# EPWM_EPWM_50020000h register map
Vendor: Texas Instruments
Registers are 16-bit, read-write, reset 0x0 unless marked. A register's access mark holds for its fields unless they carry their own. Offsets are as the file gives them; [hi:lo] are bit positions; {n}, {i} and the like mark numbered series; 'fields as' and 'values as' point back to an identical list; <NAME> marks a mode.

## EPWM (part 4 of 4)
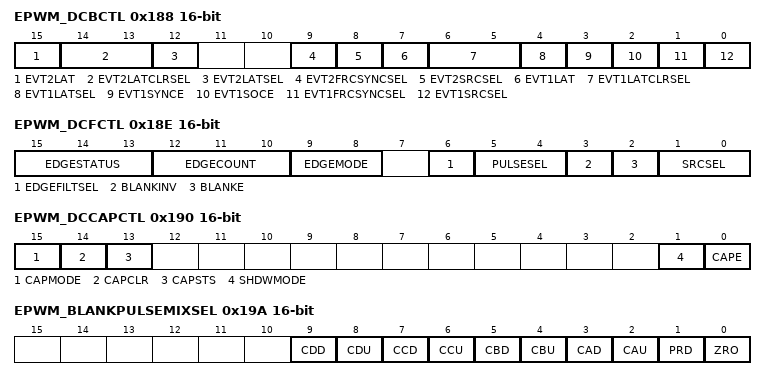
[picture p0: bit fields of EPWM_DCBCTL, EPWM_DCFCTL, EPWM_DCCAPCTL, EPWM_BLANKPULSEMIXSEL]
0x188 EPWM_DCBCTL access per field — Digital Compare B Control Register.
  [15] EVT2LAT ro — Indicates the status of DCBEVT2LAT signal. 0 The DCBEVT2LAT latch is cleared. 1 The DCBEVT2LAT latch is set.
  [14:13] EVT2LATCLRSEL rw — DCBEVT2 Latched clear source select: 00 CNT_ZERO event clears DCBEVT2 latch. 01 PRD_EQ event clears DCBEVT2 latch. 10 CNT_ZERO event or PRD_EQ event clears DCBEVT2 latch. 11 Reserved.
  [12] EVT2LATSEL rw — DCBEVT2 Latched signal select: 0 Does not select the DCBEVT2 latched signal as source of DCBEVT2.force. 1 Selects the DCBEVT2 latched signal as source of DCBEVT2.force.
  [9] EVT2FRCSYNCSEL rw — DCBEVT2 Force Synchronization Signal Select 0:Source is synchronized with EPWMCLK 1:Source is passed through asynchronously
  [8] EVT2SRCSEL rw — DCBEVT2 Source Signal Select 0:Source Is DCBEVT2 Signal 1:Source Is DCEVTFILT Signal
  [7] EVT1LAT ro — Indicates the status of DCBEVT1LAT signal. 0 The DCBEVT1LAT latch is cleared. 1 The DCBEVT1LAT latch is set.
  [6:5] EVT1LATCLRSEL rw — DCBEVT1 Latched clear source select: 00 CNT_ZERO event clears DCBEVT1 latch. 01 PRD_EQ event clears DCBEVT1 latch. 10 CNT_ZERO event or PRD_EQ event clears DCBEVT1 latch. 11 Reserved.
  [4] EVT1LATSEL rw — DCBEVT1 Latched signal select: 0 Does not select the DCBEVT1 latched signal as source of DCBEVT1.force. 1 Selects the DCBEVT1 latched signal as source of DCBEVT1.force.
  [3] EVT1SYNCE rw — DCBEVT1 SYNC, Enable/Disable 0:SYNC Generation Disabled 1:SYNC Generation Enabled
  [2] EVT1SOCE rw — DCBEVT1 SOC, Enable/Disable 0:SOC Generation Disabled 1:SOC Generation Enabled
  [1] EVT1FRCSYNCSEL rw — DCBEVT1 Force Synchronization Signal Select 0:Source is synchronized with EPWMCLK 1:Source is passed through asynchronously
  [0] EVT1SRCSEL rw — DCBEVT1 Source Signal Select 0:Source Is DCBEVT1 Signal 1:Source Is DCEVTFILT Signal
0x18E EPWM_DCFCTL access per field — Digital Compare Filter Control Register.
  [15:13] EDGESTATUS ro — Edge Status: These bits reflect the total number of edges currently captured. When the value matches the EDGECOUNT, the status bits are set to zero. and a TBCLK wide pulse is generated which can then be output on the DCEVTFILT signal. The edge counter can be reset by Writing 000 to the EDGECOUNT value:
  [12:10] EDGECOUNT rw — Edge Count: These bits select how many edges to count before generating a TBCLK wide pulse on the DCEVTFILT signal: 000:no edges, reset current EDGESTATUS bits to 3'b000 001:1 edge 010:2 edges 011:3 edges 100:4 edges 101:5 edges 110:6 edges 111:7 edges
  [9:8] EDGEMODE rw — Edge Mode Select: 00:Low To High Edge 01:High To Low Edge 10:Both Edges 11:Reserved
  [6] EDGEFILTSEL rw — Edge Filter Select: 0:Edge Filter Not Selected 1:Edge Filter Selected
  [5:4] PULSESEL rw — Pulse Select For Blanking & Capture Alignment 00:Time-base counter equal to period [TBCTR = TBPRD] 01:Time-base counter equal to zero [TBCTR = 0x00] 10:Time-base counter equal to zero [TBCTR = 0x00] or period [TBCTR = TBPRD] 11:Blank Pulse Mix
  [3] BLANKINV rw — Blanking Window Inversion 0:Blanking window not inverted 1:Blanking window inverted
  [2] BLANKE rw — Blanking Window Enable/Disable 0:Blanking window is disabled 1:Blanking window is enabled
  [1:0] SRCSEL rw — Filter Block Signal Source Select 00:Source Is DCAEVT1 Signal 01:Source Is DCAEVT2 Signal 10:Source Is DCBEVT1 Signal 11:Source Is DCBEVT2 Signal
0x190 EPWM_DCCAPCTL access not given — Digital Compare Capture Control Register.
  [15] CAPMODE rw — Counter Capture Mode 0:When a DCEVTFILT occurs and the counter capture is enabled, then the current TBCNT value is captured in the active register. When the respective trip event occurs, further trip [capture] events are ignored until the next PRD_eq or CNT_zero event [as selected by the PULSESEL bit in the DCFCTL register] re-triggers the capture mechanism. If active mode is enabled, via SHDWMODE bit in DCC0PCTL register, CPU reads of this register will return the active register value. If shadow mode is enabled, via SHDWMODE bit in DCC0PCTL register, the active register is copied to the shadow register on the PRD_eq or CNT_zero event [whichever is selected by PULSESEL bit in DCFCTL register]. CPU reads of this register will return the shadow register value. 1:When a DCEVTFILT occurs and the counter capture is enabled, then the current TBCNT value is captured in the active register. When the respective trip event occurs - it will set the CAPSTS flag and further trip [capture] events are ignored until this bit is cleared. CAPSTS can be cleared by writing to CAPCLR bit in DCC0PCTL register and it re-triggers the capture mechanism. If active mode is enabled, via SHDWMODE bit in DCC0PCTL register, CPU reads of this register will return the active register value. If shadow mode is enabled, via SHDWMODE bit in DCC0PCTL register, the active register is copied to the shadow register on the PRD_eq or CNT_zero event [whichever is selected by PULSESEL bit in DCFCTL register]. CPU reads of this register will return the shadow register value.
  [14] CAPCLR — DC Capture Latched Status Clear Flag 0:Writing a 0 has no effect. 1:Writing a 1 will clear this CAPSTS [set] condition. (access R/W1TS)
  [13] CAPSTS ro — Latched Status Flag for Capture Event 0:No DC capture event occurred. 1:A DC capture event has occurred.
  [1] SHDWMODE rw — TBCTR Counter Capture Shadow Select Mode 0:Enable shadow mode. The DCC0P active register is copied to shadow register on a TBCTR = TBPRD or TBCTR = zero event as defined by the DCFCTL[PULSESEL] bit. CPU reads of the DCC0P register will return the shadow register contents. 1:Active Mode. In this mode the shadow register is disabled. CPU reads from the DCC0P register will always return the active register contents.
  [0] CAPE rw — TBCTR Counter Capture Enable/Disable 0:Disable the time-base counter capture. 1:Enable the time-base counter capture.
0x192 EPWM_DCFOFFSET — Digital Compare Filter Offset Register .
  [15:0] DCFOFFSET — Blanking Window Offset These 16-bits specify the number of TBCLK cycles from the blanking window reference to the point when the blanking window is applied. The blanking window reference is either period or zero as defined by the DCFCTL[PULSESEL] bit. This offset register is shadowed and the active register is loaded at the reference point defined by DCFCTL[PULSESEL]. The offset counter is also initialized and begins to count down when the active register is loaded. When the counter expires, the blanking window is applied. If the blanking window is currently active, then the blanking window counter is restarted.
0x194 EPWM_DCFOFFSETCNT ro — Digital Compare Filter Offset Counter Register.
  [15:0] DCFOFFSETCNT — Blanking Offset Counter These 16-bits are read only and indicate the current value of the offset counter. The counter counts down to zero and then stops until it is re-loaded on the next period or zero event as defined by the DCFCTL[PULSESEL] bit. The offset counter is not affected by the free/soft emulation bits. That is, it will always continue to count down if the device is halted by a emulation stop.
0x196 EPWM_DCFWINDOW — Digital Compare Filter Window Register.
  [15:0] DCFWINDOW — Blanking Window Width 00h No blanking window is generated. 01-FFFFh: Specifies the width of the blanking window in TBCLK cycles. The blanking window begins when the offset counter expires. When this occurs, the window counter is loaded and begins to count down. If the blanking window is currently active and the offset counter expires, the blanking window counter is not restarted and the blanking window is cut short prematurely. Care should be taken to avoid this situation. The blanking window can cross a PWM period boundary.
0x198 EPWM_DCFWINDOWCNT ro — Digital Compare Filter Window Counter Register.
  [15:0] DCFWINDOWCNT — Blanking Window Counter These 16 bits are read only and indicate the current value of the window counter. The counter counts down to zero and then stops until it is re-loaded when the offset counter reaches zero again.
0x19A EPWM_BLANKPULSEMIXSEL — Blanking window trigger pulse select register.
  [9] CDD — Enable event time-base counter equal to CMPD when the timer is decrementing to the blanking window trigger [BLANKPULSEMIX]. 0:CMPD down-count match enable event is not enabled 1:Enable CMPD down-count match enable event
  [8] CDU — Enable event time-base counter equal to CMPD when the timer is incrementing to the blanking window trigger [BLANKPULSEMIX]. 0:CMPD up-count match enable event is not enabled 1:Enable CMPD up-count match enable event
  [7] CCD — Enable event time-base counter equal to CMPC when the timer is decrementing to the blanking window trigger [BLANKPULSEMIX]. 0:CMPC down-count match enable event is not enabled 1:Enable CMPC down-count match enable event
  [6] CCU — Enable event time-base counter equal to CMPC when the timer is incrementing to the blanking window trigger [BLANKPULSEMIX]. 0:CMPC up-count match enable event is not enabled 1:Enable CMPC up-count match enable event
  [5] CBD — Enable event time-base counter equal to CMPB when the timer is decrementing to the blanking window trigger [BLANKPULSEMIX]. 0:CMPB down-count match enable event is not enabled 1:Enable CMPB down-count match enable event
  [4] CBU — Enable event time-base counter equal to CMPB when the timer is incrementing to the mixed ET interrupt trigger signal [BLANKPULSEMIX]. 0:CMPB up-count match enable event is not enabled 1:Enable CMPB up-count match enable event
  [3] CAD — Enable event time-base counter equal to CMPA when the timer is decrementing to the blanking window trigger [BLANKPULSEMIX]. 0:CMPA down-count match enable event is not enabled 1:Enable CMPA down-count match enable event
  [2] CAU — Enable event time-base counter equal to CMPA when the timer is incrementing to the blanking window trigger [BLANKPULSEMIX]. 0:CMPA up-count match enable event is not enabled 1:Enable CMPA up-count match enable event
  [1] PRD — Enable event time-base counter equal to period [TBCTR = TBPRD] to the blanking window trigger [BLANKPULSEMIX]. 0:Period match event is not enabled 1:Enable period match event
  [0] ZRO — Enable event time-base counter equal to zero [TBCTR = 0x00] to the blanking window trigger [BLANKPULSEMIX]. 0:Zero match event is not enabled 1:Enable zero match event
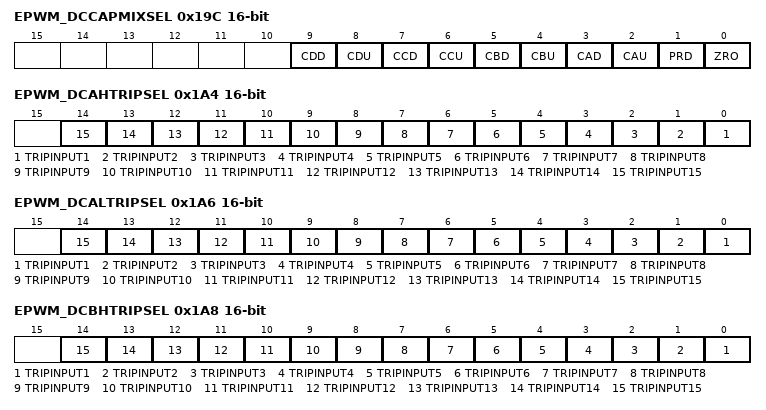
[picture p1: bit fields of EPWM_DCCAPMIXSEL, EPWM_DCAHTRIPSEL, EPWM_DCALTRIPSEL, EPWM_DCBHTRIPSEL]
0x19C EPWM_DCCAPMIXSEL — Capture Event pulse select register.
  [9] CDD — Enable event time-base counter equal to CMPD when the timer is decrementing to the blanking window trigger [DCC0PMIX]. 0:CMPD down-count match enable event is not enabled 1:Enable CMPD down-count match enable event
  [8] CDU — Enable event time-base counter equal to CMPD when the timer is incrementing to the blanking window trigger [DCC0PMIX]. 0:CMPD up-count match enable event is not enabled 1:Enable CMPD up-count match enable event
  [7] CCD — Enable event time-base counter equal to CMPC when the timer is decrementing to the blanking window trigger [DCC0PMIX]. 0:CMPC down-count match enable event is not enabled 1:Enable CMPC down-count match enable event
  [6] CCU — Enable event time-base counter equal to CMPC when the timer is incrementing to the blanking window trigger [DCC0PMIX]. 0:CMPC up-count match enable event is not enabled 1:Enable CMPC up-count match enable event
  [5] CBD — Enable event time-base counter equal to CMPB when the timer is decrementing to the blanking window trigger [DCC0PMIX]. 0:CMPB down-count match enable event is not enabled 1:Enable CMPB down-count match enable event
  [4] CBU — Enable event time-base counter equal to CMPB when the timer is incrementing to the mixed ET interrupt trigger signal [DCC0PMIX]. 0:CMPB up-count match enable event is not enabled 1:Enable CMPB up-count match enable event
  [3] CAD — Enable event time-base counter equal to CMPA when the timer is decrementing to the blanking window trigger [DCC0PMIX]. 0:CMPA down-count match enable event is not enabled 1:Enable CMPA down-count match enable event
  [2] CAU — Enable event time-base counter equal to CMPA when the timer is incrementing to the blanking window trigger [DCC0PMIX]. 0:CMPA up-count match enable event is not enabled 1:Enable CMPA up-count match enable event
  [1] PRD — Enable event time-base counter equal to period [TBCTR = TBPRD] to the blanking window trigger [DCC0PMIX]. 0:Period match event is not enabled 1:Enable period match event
  [0] ZRO — Enable event time-base counter equal to zero [TBCTR = 0x00] to the blanking window trigger [DCC0PMIX]. 0:Zero match event is not enabled 1:Enable zero match event
0x19E EPWM_DCCAP ro — Digital Compare Counter Capture Register .
  [15:0] DCCAP — Digital Compare Time-Base Counter Capture To enable time-base counter capture, set the DCC0PCLT[CAPE] bit to 1. If enabled, reflects the value of the time-base counter [TBCTR] on the low to high edge transition of a filtered [DCEVTFLT] event. Further capture events are ignored until the next period or zero as selected by the DCFCTL[PULSESEL] bit. Shadowing of DCC0P is enabled and disabled by the DCC0PCTL[SHDWMODE] bit. By default this register is shadowed. - If DCC0PCTL[SHDWMODE] = 0, then the shadow is enabled. In this mode, the active register is copied to the shadow register on the TBCTR = TBPRD or TBCTR = zero as defined by the DCFCTL[PULSESEL] bit. CPU reads of this register will return the shadow register value. - If DCC0PCTL[SHDWMODE] = 1, then the shadow register is disabled. In this mode, CPU reads will return the active register value. The active and shadow registers share the same memory map address.
0x1A4 EPWM_DCAHTRIPSEL — Digital Compare AH Trip Select .
  [n-1] TRIPINPUT{n} (n=1..15) — TRIP Input {n} 0:Trip Input {n} not selected as combinational ORed input 1:Trip Input {n} selected as combinational ORed input to DCAH mux
0x1A6 EPWM_DCALTRIPSEL — Digital Compare AL Trip Select .
  [n-1] TRIPINPUT{n} (n=1..15) — TRIP Input {n} 0:Trip Input {n} not selected as combinational ORed input 1:Trip Input {n} selected as combinational ORed input to DCAL mux
0x1A8 EPWM_DCBHTRIPSEL — Digital Compare BH Trip Select .
  [n-1] TRIPINPUT{n} (n=1..15) — TRIP Input {n} 0:Trip Input {n} not selected as combinational ORed input 1:Trip Input {n} selected as combinational ORed input to DCBH mux
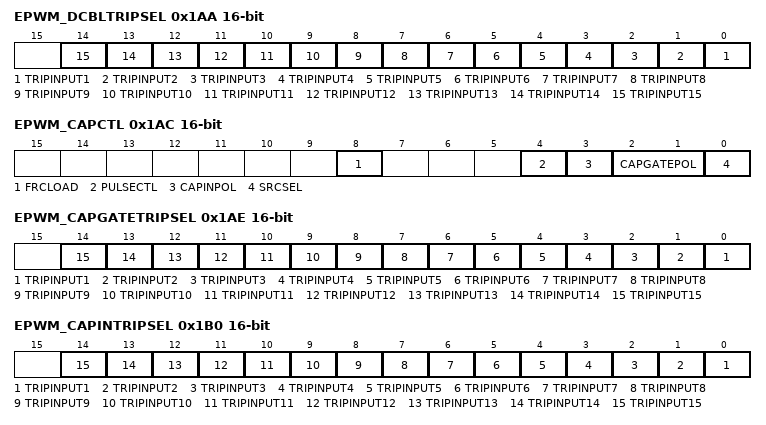
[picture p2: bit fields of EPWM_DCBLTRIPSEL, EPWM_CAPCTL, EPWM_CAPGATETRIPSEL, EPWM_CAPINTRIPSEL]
0x1AA EPWM_DCBLTRIPSEL — Digital Compare BL Trip Select .
  fields as EPWM_DCALTRIPSEL
0x1AC EPWM_CAPCTL access not given — Event Capture Control Register.
  [8] FRCLOAD — 0:Writing of 0 is ignored. Always reads back a 0. 1:Forces a LOAD to occur on the DCC0P - an equivalent LOAD.active pulse (access R/W1TS)
  [4] PULSECTL rw — Capture Input Polarity Select Mux: 0:Pulse selection determined by PULSESEL bits [common pulse selection for Blanking and Capture logic] 1:Pulse selection determined by CAPMIXSEL register [independent pulse selection for Blaning and Capture logic]
  [3] CAPINPOL rw — Capture Input Polarity Select Mux: 0:CAPIN.sync not inverted 1:CAPIN.sync Inverted Default state assumption for these inputs can be active high. If the user is providing active low signal then invert option can be configured
  [2:1] CAPGATEPOL rw — Capture Gate Input Polarity Select Mux: 00:Set to 1 - Gate is always ON 01:Set to 0 - Gate is always OFF 10:CAPGATE.sync 11:CAPGATE.sync Inverted Default state assumption for these inputs can be active high. If the user is providing active low signal then invert option can be configured
  [0] SRCSEL rw — Capture Logic Input Select Mux: 0:DCEVTFILT [Sync] - same as Type-4 1:CAPIN.sync
0x1AE EPWM_CAPGATETRIPSEL — Event Capture Gate Trip input select.
  [n-1] TRIPINPUT{n} (n=1..15) — TRIP Input {n} 0:Trip Input {n} not selected as combinational ORed input 1:Trip Input {n} selected as combinational ORed input to CAPGATE mux
0x1B0 EPWM_CAPINTRIPSEL — Event Capture Trip input select.
  [n-1] TRIPINPUT{n} (n=1..15) — TRIP Input {n} 0:Trip Input {n} not selected as combinational ORed input 1:Trip Input {n} selected as combinational ORed input to CAPIN mux
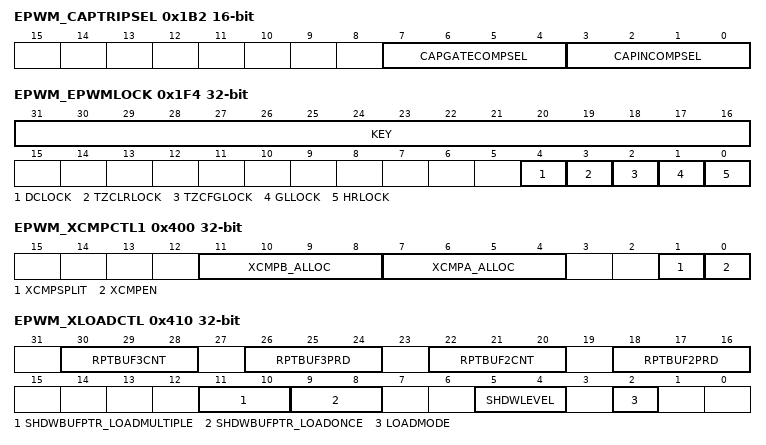
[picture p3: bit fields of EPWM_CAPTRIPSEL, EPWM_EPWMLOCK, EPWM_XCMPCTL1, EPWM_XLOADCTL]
0x1B2 EPWM_CAPTRIPSEL — Event Capture Signal Select.
  [7:4] CAPGATECOMPSEL — Digital Compare A Low Input Select Bits 0000 TRIPIN1 0001 TRIPIN2 0010 TRIPIN3 0011 TRIPIN4 ... 1011 TRIPIN12 1100 Reserved 1101 TRIPIN14 1110 TRIPIN15 1111 Trip combination input [all trip inputs selected by CAPGATETRIPSEL register ORed together]
  [3:0] CAPINCOMPSEL — Digital Compare A High Input Select Bits 0000 TRIPIN1 0001 TRIPIN2 0010 TRIPIN3 0011 TRIPIN4 ... 1011 TRIPIN12 1100 Reserved 1101 TRIPIN14 1110 TRIPIN15 1111 Trip combination input [all trip inputs selected by CAPINTRIPSEL register ORed together]
0x1F4 EPWM_EPWMLOCK 32-bit access not given — EPWM Lock Register.
  [31:16] KEY rw — Write to this register succeeds only if this field is written with a value of 0xa5a5 Note: [1] Due to this KEY, only 32-bit writes will succeed [provided the KEY matches]. 16-bit writes to the upper or lower half of this register will be ignored
  [4] DCLOCK — 0:Digital Compare registers from 0xC0 to 0xD9 offsets are protected by EALLOW. 1:Digital Compare registers from 0xC0 and 0xD9 offsets are locked and not writable. (access R/R/WONCE)
  [3] TZCLRLOCK — 0:Digital Compare registers from 0x97 to 0x9B offsets are protected by EALLOW. 1:Digital Compare registers from 0x97 and 0x9B offsets are locked and not writable. (access R/R/WONCE)
  [2] TZCFGLOCK — 0:TripZone registers from 0x80 to 0x8D and TZTRIPOUTSEL at 0x9D offsets are protected by EALLOW. 1:TripZone registers from 0x80 and 0x8D and TZTRIPOUTSEL at 0x9D offsets are locked and not writable. (access R/R/WONCE)
  [1] GLLOCK — 0:TripZone registers from 0x34 to 0x35 offsets are protected by EALLOW. 1:TripZone registers from 0x34 to 0x35 offsets are locked and not writable (access R/R/WONCE)
  [0] HRLOCK — 0: HRPWM registers from 0x20 to 0x2D offsets are protected by EALLOW 1:HRPWM registers from 0x20 and 0x2D offsets are locked and not writable. (access R/R/WONCE)
0x1FA EPWM_HWVDELVAL ro — Hardware Valley Mode Delay Register.
  [15:0] HWVDELVAL — Hardware Valley Delay Value Register This read only register reflects the hardware delay value calculated by the equations defined in VCAPCTL[VDELAYDIV]. This reflects the latest value from the hardware calculations and can change every time valley capture sequence is triggered and VCAP1 and VCAP2 values are updated.
0x1FC EPWM_VCNTVAL ro — Hardware Valley Counter Register.
  [15:0] VCNTVAL — Valley Time Base Counter Register This register reflects the captured VCNT value upon occurrence of STOPEDGE selected in VCNTCFG register.
0x400 EPWM_XCMPCTL1 32-bit — XCMP Mode Control Register.
  [11:8] XCMPB_ALLOC — XCMPn register allocation for CMPB: - 0 --> Reserved - 1 --> Reserved - 2 --> Reserved - 3 --> Reserved - 4 --> Reserved - 5 --> XCMP5 - 6 --> XCMP5, XCMP6 - 7 --> XCMP5, XCMP6, XCMP7 - 8 --> XCMP5, XCMP6, XCMP7, XCMP8 This register settings will take effect only when XCMPEN==1 And XCMPSPLIT ==1
  [7:4] XCMPA_ALLOC — XCMPn register allocation for CMPA: - 0 --> No XCMP - 1 --> XCMP1 - 2 --> XCMP1, XCMP2 - 3 --> XCMP1, XCMP2, XCMP3 - 4 --> XCMP1, XCMP2, XCMP3, XCMP4 - 5 --> XCMP1, XCMP2, XCMP3, XCMP4, XCMP5 - 6 --> XCMP1, XCMP2, XCMP3, XCMP4, XCMP5, XCMP6 - 7 --> XCMP1, XCMP2, XCMP3, XCMP4, XCMP5, XCMP6, XCMP7 - 8 --> XCMP1, XCMP2, XCMP3, XCMP4, XCMP5, XCMP6, XCMP7, XCMP8 This register settings will take effect only when XCMPEN==1 If XCMPSPLIT ==1, this field cannot be greater than 4. If XCMPSPLIT ==1 only lower 3 bits are used in this field.
  [1] XCMPSPLIT — XCMP Register Allocation Options: 0 : XCMP1-8 --> CMPA 1 : XCMP1-4 -->CMPA, XCMP5-8 CMPB This register settings will take effect only when XCMPEN==1
  [0] XCMPEN — XCMP Compare Register Operation Enable: 0 XCMP register operation Disabled [operation compatible to Type-4] 1 XCMP register operation Enabled [New CMPx registers are effective - section 1.3 details the operation]
0x410 EPWM_XLOADCTL 32-bit access per field — XCMP Mode Load Control Register.
  [30:28] RPTBUF3CNT ro — Repeat Count Status Shadow Buffer3:These bits indicate how many times shadow buffer 3 has been be applied before moving to the next buffer I,e, shadow buffer 1. 3'b000 Shadow buffer reset value with STARTLD and copied to Active register 3'b001 Shadow buffer applied twice on 2 successive load strobes 3'b010 Shadow buffer applied thrice on 3 successive load strobes . . 3'b111 Shadow buffer applied 8 times on 8 successive load strobes These bits reset to zero every time STARTLD is initiated.
  [26:24] RPTBUF3PRD rw — Repeat Count Shadow Buffer3 : These bits indicate how many times shadow buffer 3 will be applied before moving to the next buffer I,e, shadow buffer 1. 3'b000 Apply shadow buffer once and move to the next shadow buffer on the following load pulse 3'b001 Apply shadow buffer twice on 2 successive load strobes and move to the next shadow buffer on the following load pulse 3'b010 Apply shadow buffer thrice on 3 successive load strobes and move to the next shadow buffer on the following load pulse . . 3'b111 Apply shadow buffer 8 times on 8 successive load strobes and move to the next shadow buffer on the following load pulse
  [22:20] RPTBUF2CNT ro — Repeat Count Status Shadow Buffer2:These bits indicate how many times shadow buffer 2 has been be applied before moving to the next buffer I,e, shadow buffer 1. 3'b000 Shadow buffer reset value with STARTLD and copied to Active register 3'b001 Shadow buffer applied twice on 2 successive load strobes 3'b010 Shadow buffer applied thrice on 3 successive load strobes . . 3'b111 Shadow buffer applied 8 times on 8 successive load strobes These bits reset to zero every time STARTLD is initiated.
  [18:16] RPTBUF2PRD rw — Repeat Count Shadow Buffer2 : These bits indicate how many times shadow buffer 2 will be applied before moving to the next buffer I,e, shadow buffer 1. 3'b000 Apply shadow buffer once and move to the next shadow buffer on the following load pulse 3'b001 Apply shadow buffer twice on 2 successive load strobes and move to the next shadow buffer on the following load pulse 3'b010 Apply shadow buffer thrice on 3 successive load strobes and move to the next shadow buffer on the following load pulse . . 2'b12'b11 Apply shadow buffer 8 times on 8 successive load strobes and move to the next shadow buffer on the following load pulse
  [11:10] SHDWBUFPTR_LOADMULTIPLE ro — Register Load event count: These bits indicate the current shadow buffer in use. 2'b00 Reset value 0,1 1 Shadow buffer 1 in use 2'b10 2 Shadow buffer 2 in use 2'b11 3 Shadow buffer 3 in use
  [9:8] SHDWBUFPTR_LOADONCE rw — Register Load event count: These bits indicate the current shadow buffer in use. 2'b00 Reset value 0,1 1 Shadow buffer 1 in use 2'b10 2 Shadow buffer 2 in use 2'b11 3 Shadow buffer 3 in use
  [5:4] SHDWLEVEL rw — Shadow Register Level Allocation Options: These bits are effective only when XCMPEN is enabled. 2'b00 : XXXX Shadow level is set at zero. XXXX Active register is available 2'b01 : XXXX Shadow level is set at 1. XXXX_SHDW1 and Active registers are available 2'b10 : XXXX Shadow level is set at 1. XXXX_SHDW1, XXXX_SHDW2 and Active registers are available 2'b11 : XXXX Shadow level is set at 1. XXXX_SHDW1, XXXX_SHDW2, XXXX_SHDW3 and Active registers are available
  [2] LOADMODE rw — Load mode selection for Shadow registers: These bits are effective only when XCMPEN is enabled. 0 : [LOADONCE] Load occurs at every load strobe [CNT_Zero or FRCLD] from SHDWn Active registers. And STARTLD is cleared after 1 load strobe. SHDWBUFPTR is not automatically decremented in this case. User would set the SHDWBUFPTR for subsequent loads. 1 : [LOADMULTIPLE] Load occurs at every load strobe [CNT_Zero or FRCLD] from SHDWnActive registers. And STARTLD is cleared after SHDWLEVEL number of load strobes. SHDWBUFPTR decrements by 1 on a load strobe, until the SHDWBUFPTR reaches 1.
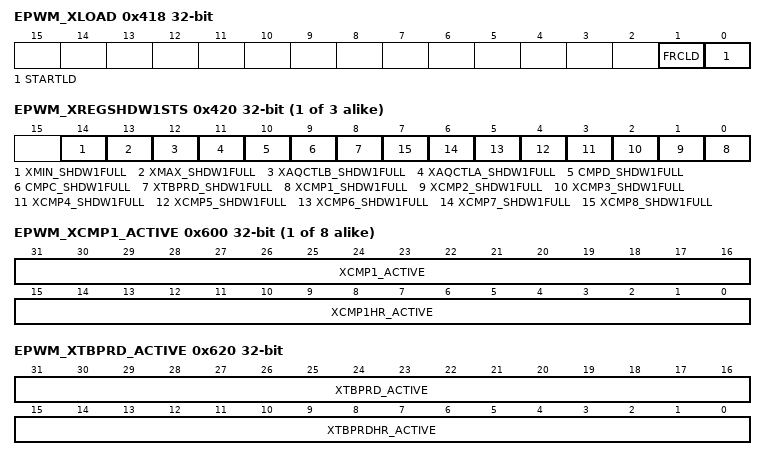
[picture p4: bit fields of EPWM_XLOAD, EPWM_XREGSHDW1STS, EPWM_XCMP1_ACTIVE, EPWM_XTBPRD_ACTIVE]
0x418 EPWM_XLOAD 32-bit access not given — XCMP Mode Load Enable Register.
  [1] FRCLD — Force reload event in one shot mode : Writing a 1 to this bit turn force one load event at the input of the event pre-scale counter as shown in the diagram below. This bit is intended to be used for testing and/or software force loading of the events in global load mode. Writing of 0 will be ignored. Always reads back a 0. (access R/W1TS)
  [0] STARTLD — Enable reload event : Writing a 1 to this bit turn the one shot latch condition ON. Upon occurrence of a chosen load strobe, one shadow to active reload occurs and the latch will be cleared. Hence Writing '1' to this bit would allow load strobe event to pass through and block further strobe events. Writing of 0 will be ignored. Always reads back a 0. (access R/W1TS)
0x41C EPWM_EPWMXLINKXLOAD 32-bit — Link register across PWM modules.
  [4:0] XLOADLINK — XLOAD Link Bits: Writes to the XLOAD registers in the EPWM module selected by the following bit selections results in a simultaneous write to the current EPWM module's XLOAD registers 5'b00000: EPWM0 5'b00001: EPWM1 5'b00010: EPWM2 5'b00011: EPWM3 5'b00100: EPWM4 5'b00101: EPWM5 5'b00110: EPWM6 5'b00111: EPWM7 5'b01000: EPWM8 5'b01001: EPWM9 5'b01010: EPWM10 5'b01011: EPWM11 5'b01100: EPWM12 ... 5'b11111: EPWM31
{0x418+8i} EPWM_XREGSHDW{i}STS 32-bit ro (i=1..3) — Shadow Buffer {i} Update Status Register.
  [14] XMIN_SHDW{i}FULL — 0 Shadow Register is not full yet 1 Indicates the Shadow Register is full, a CPU write will over-write current Shadow value
  [13] XMAX_SHDW{i}FULL — 0 Shadow Register is not full yet 1 Indicates the Shadow Register is full, a CPU write will over-write current Shadow value
  [12] XAQCTLB_SHDW{i}FULL — 0 Shadow Register is not full yet 1 Indicates the Shadow Register is full, a CPU write will over-write current Shadow value
  [11] XAQCTLA_SHDW{i}FULL — 0 Shadow Register is not full yet 1 Indicates the Shadow Register is full, a CPU write will over-write current Shadow value
  [10] CMPD_SHDW{i}FULL — 0 Shadow Register is not full yet 1 Indicates the Shadow Register is full, a CPU write will over-write current Shadow value
  [9] CMPC_SHDW{i}FULL — 0 Shadow Register is not full yet 1 Indicates the Shadow Register is full, a CPU write will over-write current Shadow value
  [8] XTBPRD_SHDW{i}FULL — 0 Shadow Register is not full yet 1 Indicates the Shadow Register is full, a CPU write will over-write current Shadow value
  [n-1] XCMP{n}_SHDW{i}FULL (n=1..8) — 0 Shadow Register is not full yet 1 Indicates the Shadow Register is full, a CPU write will over-write current Shadow value
{0x5FC+4i} EPWM_XCMP{i}_ACTIVE 32-bit (i=1..8) — Additional Compare {i} Active Register.
  [31:16] XCMP{i}_ACTIVE — XCMP{i}_ACTIVE Register The value in the XCMP{i}_ACTIVE register is loaded into CMPA/B [shadow/active] registers when shadow to active load occurs.
  [15:0] XCMP{i}HR_ACTIVE — XCMP{i}HR_ACTIVE Register The value in the XCMP{i}HR_ACTIVE register is loaded into CMPA/BHR [shadow/active] registers when shadow to active load occurs.
0x620 EPWM_XTBPRD_ACTIVE 32-bit — Additional Time Base Period Active Register.
  [31:16] XTBPRD_ACTIVE — The value in the XTBPRD_ACTIVE register is loaded into TBPRD [shadow/active] registers when shadow to active load occurs.
  [15:0] XTBPRDHR_ACTIVE — The value in the XTBPRDHR_ACTIVE register is loaded into TBPRDHR [shadow/active] registers when shadow to active load occurs.
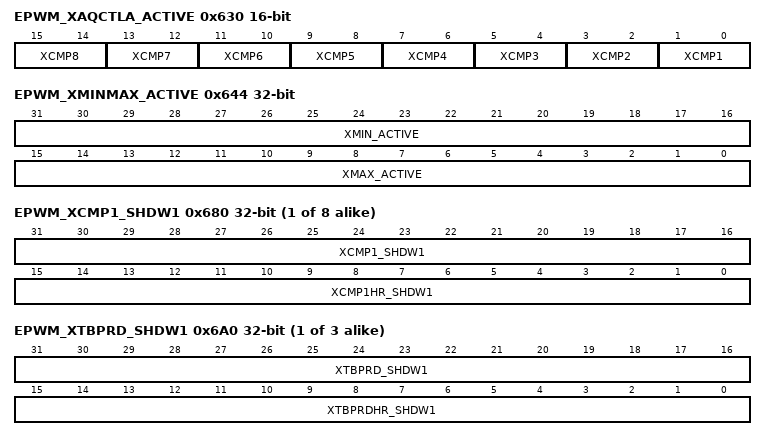
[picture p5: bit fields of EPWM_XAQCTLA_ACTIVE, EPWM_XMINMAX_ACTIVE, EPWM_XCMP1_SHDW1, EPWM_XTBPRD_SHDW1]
0x630 EPWM_XAQCTLA_ACTIVE — AQCTLA Active Register.
  [2n-1:2n-2] XCMP{n} (n=1..8) — Action when Counter = CMP{n} 2'b00 Do nothing [action disabled] 2'b01 Clear [low] 2'b10 Set [high] 2'b11 Toggle [Low -> High, High -> Low]
0x644 EPWM_XMINMAX_ACTIVE 32-bit — XMINMAX Active Register.
  [31:16] XMIN_ACTIVE — The value in the XMIN_ACTIVE register is used for comparision against the threshold of the capture counter at any given time.
  [15:0] XMAX_ACTIVE — The value in the XMAX_ACTIVE register is used for comparision against the threshold of the capture counter at any given time.
{0x67C+4i} EPWM_XCMP{i}_SHDW1 32-bit (i=1..8) — Additional Compare {i} Shadow 1 Register.
  [31:16] XCMP{i}_SHDW1 — XCMP{i}_SHDW1 Register The value in the XCMP{i}_SHDW1 register is loaded into XCMP{i}_ACTIVE register when shadow to active load occurs.
  [15:0] XCMP{i}HR_SHDW1 — XCMP{i}HR_SHDW1 Register The value in the XCMP{i}HR_SHDW1 register is loaded into XCMP{i}HR_ACTIVE register when shadow to active load occurs.
{0x620+0x80*i} EPWM_XTBPRD_SHDW{i} 32-bit (i=1..3) — Additional Time Base Period Shadow {i} Register.
  [31:16] XTBPRD_SHDW{i} — The value in the XTBPRD_SHDW{i} register is loaded into XTBPRD_ ACTIVE register when shadow to active load occurs.
  [15:0] XTBPRDHR_SHDW{i} — The value in the XTBPRDHR_SHDW{i} register is loaded into XTBPRDHR_ACTIVE register when shadow to active load occurs.
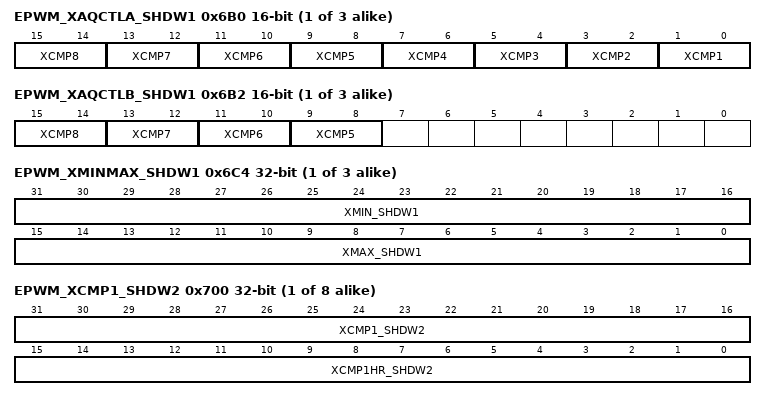
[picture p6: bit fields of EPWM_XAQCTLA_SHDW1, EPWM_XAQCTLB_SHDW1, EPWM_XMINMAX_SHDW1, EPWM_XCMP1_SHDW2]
{0x630+0x80*i} EPWM_XAQCTLA_SHDW{i} (i=1..3) — XAQCTLA Shadow {i} Register.
  fields as EPWM_XAQCTLA_ACTIVE
{0x632+0x80*i} EPWM_XAQCTLB_SHDW{i} (i=1..3) — XAQCTLB Shadow {i} Register.
  [2n-1:2n-2] XCMP{n} (n=5..8) — Action when Counter = CMP{n} 2'b00 Do nothing [action disabled] 2'b01 Clear [low] 2'b10 Set [high] 2'b11 Toggle [Low -> High, High -> Low]
{0x63A+0x80*i} EPWM_CMPC_SHDW{i} (i=1..3) — CMPC Shadow {i} Register.
  [15:0] CMPC_SHDW{i} — The value in the CMPC_SHDW{i} register is loaded into CMPC_ACTIVE register when shadow to active load occurs.
{0x63E+0x80*i} EPWM_CMPD_SHDW{i} (i=1..3) — CMPD Shadow {i} Register.
  [15:0] CMPD_SHDW{i} — The value in the CMPD_SHDW{i} register is loaded into CMPD_ACTIVE register when shadow to active load occurs.
{0x644+0x80*i} EPWM_XMINMAX_SHDW{i} 32-bit (i=1..3) — XMINMAX Shadow {i} Register.
  [31:16] XMIN_SHDW{i} — The value in the XMIN_SHDW{i} register is loaded into XMIN_ACTIVE register when shadow to active load occurs.
  [15:0] XMAX_SHDW{i} — The value in the XMAX_SHDW{i} register is loaded into XMAX_ACTIVE register when shadow to active load occurs.
{0x6FC+4i} EPWM_XCMP{i}_SHDW2 32-bit (i=1..8) — Additional Compare {i} Shadow 2 Register.
  [31:16] XCMP{i}_SHDW2 — XCMP{i}_SHDW2 Register The value in the XCMP{i}_SHDW2 register is loaded into XCMP{i}_ACTIVE register when shadow to active load occurs.
  [15:0] XCMP{i}HR_SHDW2 — XCMP{i}HR_SHDW2 Register The value in the XCMP{i}HR_SHDW2 register is loaded into XCMP{i}HR_ACTIVE register when shadow to active load occurs.
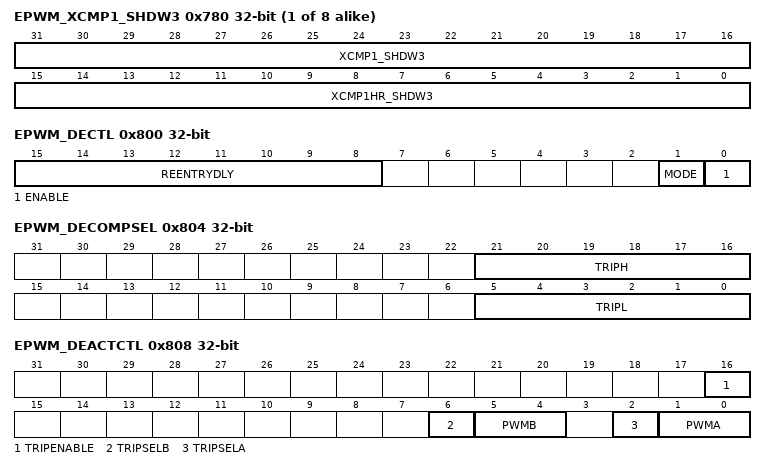
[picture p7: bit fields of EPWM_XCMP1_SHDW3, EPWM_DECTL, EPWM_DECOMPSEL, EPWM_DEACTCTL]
{0x77C+4i} EPWM_XCMP{i}_SHDW3 32-bit (i=1..8) — Additional Compare {i} Shadow 3 Register.
  [31:16] XCMP{i}_SHDW3 — XCMP{i}_SHDW3 Register The value in the XCMP{i}_SHDW3 register is loaded into XCMP{i}_ACTIVE register when shadow to active load occurs.
  [15:0] XCMP{i}HR_SHDW3 — XCMP{i}HR_SHDW3 Register The value in the XCMP{i}HR_SHDW3 register is loaded into XCMP{i}HR_ACTIVE register when shadow to active load occurs.
0x800 EPWM_DECTL 32-bit — DE control register.
  [15:8] REENTRYDLY — Determines the blocking window after DEACTIVE flag is cleared in which setting of DEACTIVE flag is prevented from being set. 0 : No blocking 1 : Blocked until 1 PWMSYNCOUT event 2 : Blocked until 2 PWMSYNCOUT events . . 255 : Blocked until 127 PWMSYNCOUT events
  [1] MODE — 0 : DEACTIVE flag works in cycle by cycle mode. On every PWMSYNCOUT, set condition of DEACTIVE flag is evaluated. If the set condition is not present the flag is cleared. 1 : DEACTIVE flag works in one shot mode [hardware set] and software clear.
  [0] ENABLE — DE function enable 0 : Diode Emulation mode functionality is disabled. DEACTIVE flag is not set on a TRIPH_OR_TRIPL event. 1 : Diode Emulation mode functionality is enabled. DEACTIVE flag is set on a TRIPH_OR_TRIPL event. Note: ENABLE bit is cleared on a PWMTRIP event. Software has to re-enable this bit after PWMTRIP condition is serviced.
0x804 EPWM_DECOMPSEL 32-bit — Used to configure the comparator whose trip sources will be used.
  [21:16] TRIPH — 000000 : Reserved000001 : Input-XBAR[0] is the source of TRIPH000010 : Input-XBAR[1] is the source of TRIPH..100000 : Input-XBAR[31] is the source of TRIPH100001 : CMPSSA0 is the source of TRIPH100010 : CMPSSA1 is the source of TRIPH..101010 : CMPSSA9 is the source of TRIPH101011 : Reserved..110000 : Reserved110001 : CMPSSB0 is the source of TRIPH110010 : CMPSSB1 is the source of TRIPH..111010 : CMPSSB9 is the source of TRIPH111011 : Reserved..111111 : ReservedNote: All the reserved encodings result in TRIPH being 0.
  [5:0] TRIPL — 000000 : Reserved000001 : Input-XBAR[0] is the source of TRIPL000010 : Input-XBAR[1] is the source of TRIPL..100000 : Input-XBAR[31] is the source of TRIPL100001 : CMPSSA0 is the source of TRIPL100010 : CMPSSA1 is the source of TRIPL..101010 : CMPSSA9 is the source of TRIPL101011 : Reserved..110000 : Reserved110001 : CMPSSB0 is the source of TRIPL110010 : CMPSSB1 is the source of TRIPL..111010 : CMPSSB9 is the source of TRIPL111011 : Reserved..111111 : ReservedNote: All the reserved encodings result in TRIPL being 0.
0x808 EPWM_DEACTCTL 32-bit — Used to configure the PWM controls when in DE mode.
  [16] TRIPENABLE — 0 : PWMTRIP does not bypass the diode emulation logic. 1 : PWMTRIP bypasses the diode emulation PWM generation logic [not complete bypass of module]
  [6] TRIPSELB — 0 : TRIPH 1 : TRIPL
  [5:4] PWMB — 00 : synchronized version of TRIPH or TRIPL signal as selected by the TRIPSELB 01 : synchronized and inverted version of TRIPH or TRIPL signal as selected by the TRIPSELB 10 : A constant 0 drives PWMB when DEACTIVE flag is set. 11 : A constant 1 drives PWMB when DEACTIVE flag is set.
  [2] TRIPSELA — 0 : TRIPH 1 : TRIPL
  [1:0] PWMA — 00 : synchronized version of TRIPH or TRIPL signal as selected by the TRIPSELA 01 : synchronized and inverted version of TRIPH or TRIPL signal as selected by the TRIPSELA 10 : A constant 0 drives PWMA when DEACTIVE flag is set. 11 : A constant 1 drives PWMA when DEACTIVE flag is set.
0x80C EPWM_DESTS 32-bit ro — DE Status register.
  [0] DEACTIVE — 0 : Diode emulation mode is not active 1 : Diode emulation mode is active
0x810 EPWM_DEFRC 32-bit access not given — DE Status force register.
  [0] DEACTIVE — 0 : No effect. 1 : Forces DEACTIVE flag to 1. (access R/W1TS)
0x814 EPWM_DECLR 32-bit access not given — DE Status clear register.
  [0] DEACTIVE — 0 : No effect. 1 : Clears DEACTIVE flag. (access R/W1TS)
0x820 EPWM_DEMONCNT 32-bit ro — DE trip monitor counter.
  [15:0] CNT — An 16-bit counter which monitors the frequency of diode mode trip events. When TripHorTripL is active: Increment CNT [increment INCSTEP on every EPWMxSYNC] When TripHorTripL is in-active: Decrement CNT [decrement DECSTEP on every EPWMxSYNC] If[ CNT > THRESHOLD] then generate DETRIP and clear the counter. If[ [CNT - DECSTEP] < 0] then CNT = 0 If[ [CNT + INCSTEP] >= 0xFFFF] then CNT = 0xFFFF Note : CNT is cleared when DECTL.ENABLE is 0 Note: DEMONTHRES == 0x0 should not generate trip as the DEMONTHRES and DEMONCNT registers have reset value of 0x0
0x824 EPWM_DEMONCTL 32-bit — DE monitor mode control.
  [0] ENABLE — Enable bit for DE Mode Monitor counter function. 0:DE Mode Monitor counter function is disabled 1:DE Mode Monitor counter function is enabled
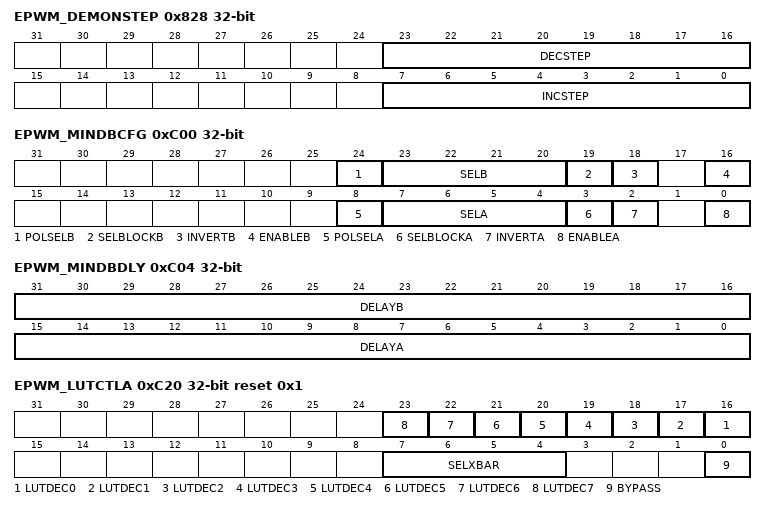
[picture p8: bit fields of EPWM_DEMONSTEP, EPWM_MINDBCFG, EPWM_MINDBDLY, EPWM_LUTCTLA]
0x828 EPWM_DEMONSTEP 32-bit — DE monitor counter step.
  [23:16] DECSTEP — Defines the decrement step of DEMONCNT.CNT counter.
  [7:0] INCSTEP — Defines the increment step of DEMONCNT.CNT counter.
0x82C EPWM_DEMONTHRES 32-bit — DE monitor counter threshold.
  [15:0] THRESHOLD — Defines the threshold of DE monitor counter.
0xC00 EPWM_MINDBCFG 32-bit — Minimum dead band configuration register.
  [24] POLSELB — Select signal for the AND OR logic of BLOCKB [output of SELBLOCKB mux] and PWMB signals 0 : Select BLOCKB is inverted and ANDed with PWMB. 1 : Select BLOCKB is Ored with PWMB.
  [23:20] SELB — PWMB min dead band reference 0x0 : DEPWMB 0x1 : Output 1 from PWMXBAR 0x2 : Output 2 from PWMXBAR . . 0xf : Output 15 from PWMXBAR
  [19] SELBLOCKB — 0 : Select BLOCKB as the blocking signal on PWMB. 1 : Select BLOCKA as the blocking signal on PWMB.
  [18] INVERTB — 0 : No inversion on the selected reference signal which is used in the min deadband logic on PWMB. 1 : Invert the selected reference signal which is used in the min deadband logic on PWMB.
  [16] ENABLEB — 0 : Minimum dead band logic is disabled 1 : Minimum dead band logic is enabled
  [8] POLSELA — Select signal for the AND OR logic of BLOCKA [output of SELBLOCKA mux] and PWMA signals 0 : Select BLOCKA is inverted and ANDed with PWMA. 1 : Select BLOCKA is Ored with PWMA.
  [7:4] SELA — PWMA min dead band reference 0x0 : DEPWMA 0x1 : Output 1 from PWMXBAR 0x2 : Output 2 from PWMXBAR . . 0xf : Output 15 from PWMXBAR
  [3] SELBLOCKA — 0 : Select BLOCKA as the blocking signal on PWMA. 1 : Select BLOCKB as the blocking signal on PWMB.
  [2] INVERTA — 0 : No inversion on the selected reference signal which is used in the min deadband logic on PWMA. 1 : Invert the selected reference signal which is used in the min deadband logic on PWMA.
  [0] ENABLEA — 0 : Minimum dead band logic is disabled 1 : Minimum dead band logic is enabled
0xC04 EPWM_MINDBDLY 32-bit — Minimum dead band delay register.
  [31:16] DELAYB — Minimum dead band delay on PWMB in terms of SYSCLK cycles. For delay value of 0, user should configure MINDBCFG[ENABLEA/B] = '0'. If MINDBCFG[ENABLEA/B] = '1' and MINDBDLY[DELAYA/B]='0' then delay is '1' cycle is applied.
  [15:0] DELAYA — Minimum dead band delay on PWMA in terms of SYSCLK cycles. For delay value of 0, user should configure MINDBCFG[ENABLEA/B] = '0'. If MINDBCFG[ENABLEA/B] = '1' and MINDBDLY[DELAYA/B]='0' then delay is '1' cycle is applied.
0xC20 EPWM_LUTCTLA 32-bit reset 0x1 — LUT control register on PWMA.
  [n+16] LUTDEC{n} (n=0..7) — 0 : Force 0 1 : Force 1
  [7:4] SELXBAR — Selects one of the 16 outputs of ICSSXBAR to feed into IN3 of LUTA
  [0] BYPASS — 1 : Bypass LUT logic on PWMA 0 : PWMA driven by LUTA
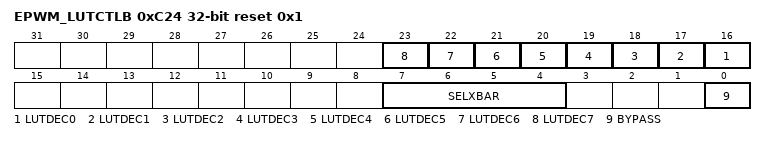
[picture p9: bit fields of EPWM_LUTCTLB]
0xC24 EPWM_LUTCTLB 32-bit reset 0x1 — LUT control register on PWMB.
  [n+16] LUTDEC{n} (n=0..7) — 0 : Force 0 1 : Force 1
  [7:4] SELXBAR — Selects one of the 16 outputs of ICSSXBAR to feed into IN3 of LUTB
  [0] BYPASS — 1 : Bypass LUT logic on PWMB 0 : PWMB driven by LUTB
